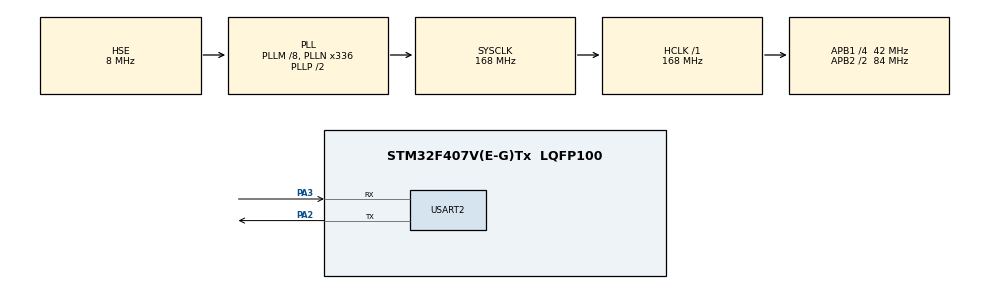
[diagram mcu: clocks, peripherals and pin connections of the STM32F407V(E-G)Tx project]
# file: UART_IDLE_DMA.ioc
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Dma.Request0=USART2_RX
Dma.USART2_RX.0.Direction=DMA_PERIPH_TO_MEMORY
Dma.USART2_RX.0.FIFOMode=DMA_FIFOMODE_DISABLE
Dma.USART2_RX.0.Instance=DMA1_Stream5
Dma.USART2_RX.0.MemDataAlignment=DMA_MDATAALIGN_BYTE
Dma.USART2_RX.0.MemInc=DMA_MINC_ENABLE
Dma.USART2_RX.0.Mode=DMA_CIRCULAR
Dma.USART2_RX.0.PeriphDataAlignment=DMA_PDATAALIGN_BYTE
Dma.USART2_RX.0.PeriphInc=DMA_PINC_DISABLE
Dma.USART2_RX.0.Priority=DMA_PRIORITY_LOW
Mcu.Family=STM32F4
Mcu.Name=STM32F407V(E-G)Tx
Mcu.Package=LQFP100
NVIC.DMA1_Stream5_IRQn=true\:0\:0\:false\:false\:true\:false\:true\:true
NVIC.PriorityGroup=NVIC_PRIORITYGROUP_0
NVIC.USART2_IRQn=true\:0\:0\:false\:false\:true\:true\:true\:true
PA13.Mode=Serial_Wire
PA13.Signal=SYS_JTMS-SWDIO
PA14.Mode=Serial_Wire
PA14.Signal=SYS_JTCK-SWCLK
PA2.Mode=Asynchronous
PA2.Signal=USART2_TX
PA3.Mode=Asynchronous
PA3.Signal=USART2_RX
PH0-OSC_IN.Mode=HSE-External-Oscillator
PH0-OSC_IN.Signal=RCC_OSC_IN
PH1-OSC_OUT.Mode=HSE-External-Oscillator
PH1-OSC_OUT.Signal=RCC_OSC_OUT
ProjectManager.HeapSize=0x200
ProjectManager.StackSize=0x400
ProjectManager.TargetToolchain=STM32CubeIDE
RCC.48MHZClocksFreq_Value=48000000
RCC.AHBFreq_Value=168000000
RCC.APB1CLKDivider=RCC_HCLK_DIV4
RCC.APB1Freq_Value=42000000
RCC.APB1TimFreq_Value=84000000
RCC.APB2CLKDivider=RCC_HCLK_DIV2
RCC.APB2Freq_Value=84000000
RCC.APB2TimFreq_Value=168000000
RCC.CortexFreq_Value=168000000
RCC.HCLKFreq_Value=168000000
RCC.HSE_VALUE=8000000
RCC.HSI_VALUE=16000000
RCC.LSE_VALUE=32768
RCC.PLLM=8
RCC.PLLN=336
RCC.PLLQ=7
RCC.PLLSourceVirtual=RCC_PLLSOURCE_HSE
RCC.SYSCLKFreq_VALUE=168000000
RCC.SYSCLKSource=RCC_SYSCLKSOURCE_PLLCLK
RCC.VCOOutputFreq_Value=336000000
USART2.VirtualMode=VM_ASYNC
board=STM32F407G-DISC1

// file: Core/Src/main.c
/* USER CODE BEGIN Header */
/**
  ******************************************************************************
  * @file           : main.c
  * @brief          : Main program body
  ******************************************************************************
  * @attention
  *
  * Copyright (c) 2026 STMicroelectronics.
  * All rights reserved.
  *
  * This software is licensed under terms that can be found in the LICENSE file
  * in the root directory of this software component.
  * If no LICENSE file comes with this software, it is provided AS-IS.
  *
  ******************************************************************************
  */
/* USER CODE END Header */
#include "main.h"

/* USER CODE BEGIN Includes */
#include "uart_rx.h"
#include "tests.h"
/* USER CODE END Includes */

UART_HandleTypeDef huart2;
DMA_HandleTypeDef hdma_usart2_rx;
DMA_HandleTypeDef hdma_usart2_tx;

void SystemClock_Config(void);
static void MX_GPIO_Init(void);
static void MX_DMA_Init(void);
static void MX_USART2_UART_Init(void);

int main(void)
{

  /* MCU Configuration--------------------------------------------------------*/

  /* Reset of all peripherals, Initializes the Flash interface and the Systick. */
  HAL_Init();

  /* Configure the system clock */
  SystemClock_Config();

  /* Initialize all configured peripherals */
  MX_GPIO_Init();
  MX_DMA_Init();
  MX_USART2_UART_Init();
  /* USER CODE BEGIN 2 */
  /* Donanim gerektirmeyen 27 birim testi. Uretimde kaldirilabilir. */
  birim_testleri_kosur();

  /* Alimi baslat: ayristirici ve okuma konumu sifirlanir, circular DMA
     IDLE olaylariyla kurulur. Loopback gonderiminden ONCE olmali. */
  if (uart_rx_start(&huart2) != HAL_OK)
  {
    Error_Handler();
  }

  /* PA2-PA3 jumper gerektirir. Uretimde kaldirilabilir. */
  loopback_testi_kosur(&huart2);
  /* USER CODE END 2 */

  /* Infinite loop */
  while (1)
  {

    /* USER CODE BEGIN 3 */
    uart_rx_service();
  }
  /* USER CODE END 3 */
}

void SystemClock_Config(void)
{
  RCC_OscInitTypeDef RCC_OscInitStruct = {0};
  RCC_ClkInitTypeDef RCC_ClkInitStruct = {0};

  /** Configure the main internal regulator output voltage
  */
  __HAL_RCC_PWR_CLK_ENABLE();
  __HAL_PWR_VOLTAGESCALING_CONFIG(PWR_REGULATOR_VOLTAGE_SCALE1);

  /** Initializes the RCC Oscillators according to the specified parameters
  * in the RCC_OscInitTypeDef structure.
  */
  RCC_OscInitStruct.OscillatorType = RCC_OSCILLATORTYPE_HSE;
  RCC_OscInitStruct.HSEState = RCC_HSE_ON;
  RCC_OscInitStruct.PLL.PLLState = RCC_PLL_ON;
  RCC_OscInitStruct.PLL.PLLSource = RCC_PLLSOURCE_HSE;
  RCC_OscInitStruct.PLL.PLLM = 8;
  RCC_OscInitStruct.PLL.PLLN = 336;
  RCC_OscInitStruct.PLL.PLLP = RCC_PLLP_DIV2;
  RCC_OscInitStruct.PLL.PLLQ = 7;
  if (HAL_RCC_OscConfig(&RCC_OscInitStruct) != HAL_OK)
  {
    Error_Handler();
  }

  /** Initializes the CPU, AHB and APB buses clocks
  */
  RCC_ClkInitStruct.ClockType = RCC_CLOCKTYPE_HCLK|RCC_CLOCKTYPE_SYSCLK
                              |RCC_CLOCKTYPE_PCLK1|RCC_CLOCKTYPE_PCLK2;
  RCC_ClkInitStruct.SYSCLKSource = RCC_SYSCLKSOURCE_PLLCLK;
  RCC_ClkInitStruct.AHBCLKDivider = RCC_SYSCLK_DIV1;
  RCC_ClkInitStruct.APB1CLKDivider = RCC_HCLK_DIV4;
  RCC_ClkInitStruct.APB2CLKDivider = RCC_HCLK_DIV2;

  if (HAL_RCC_ClockConfig(&RCC_ClkInitStruct, FLASH_LATENCY_5) != HAL_OK)
  {
    Error_Handler();
  }
}

static void MX_USART2_UART_Init(void)
{

  huart2.Instance = USART2;
  huart2.Init.BaudRate = 115200;
  huart2.Init.WordLength = UART_WORDLENGTH_8B;
  huart2.Init.StopBits = UART_STOPBITS_1;
  huart2.Init.Parity = UART_PARITY_NONE;
  huart2.Init.Mode = UART_MODE_TX_RX;
  huart2.Init.HwFlowCtl = UART_HWCONTROL_NONE;
  huart2.Init.OverSampling = UART_OVERSAMPLING_16;
  if (HAL_UART_Init(&huart2) != HAL_OK)
  {
    Error_Handler();
  }

}

static void MX_DMA_Init(void)
{

  /* DMA controller clock enable */
  __HAL_RCC_DMA1_CLK_ENABLE();

  /* DMA interrupt init */
  /* DMA1_Stream5_IRQn interrupt configuration */
  HAL_NVIC_SetPriority(DMA1_Stream5_IRQn, 0, 0);
  HAL_NVIC_EnableIRQ(DMA1_Stream5_IRQn);
  /* DMA1_Stream6_IRQn interrupt configuration */
  HAL_NVIC_SetPriority(DMA1_Stream6_IRQn, 0, 0);
  HAL_NVIC_EnableIRQ(DMA1_Stream6_IRQn);

}

static void MX_GPIO_Init(void)
{

  /* GPIO Ports Clock Enable */
  __HAL_RCC_GPIOH_CLK_ENABLE();
  __HAL_RCC_GPIOA_CLK_ENABLE();

}

void Error_Handler(void)
{
  __disable_irq();
  while (1)
  {
  }
}
